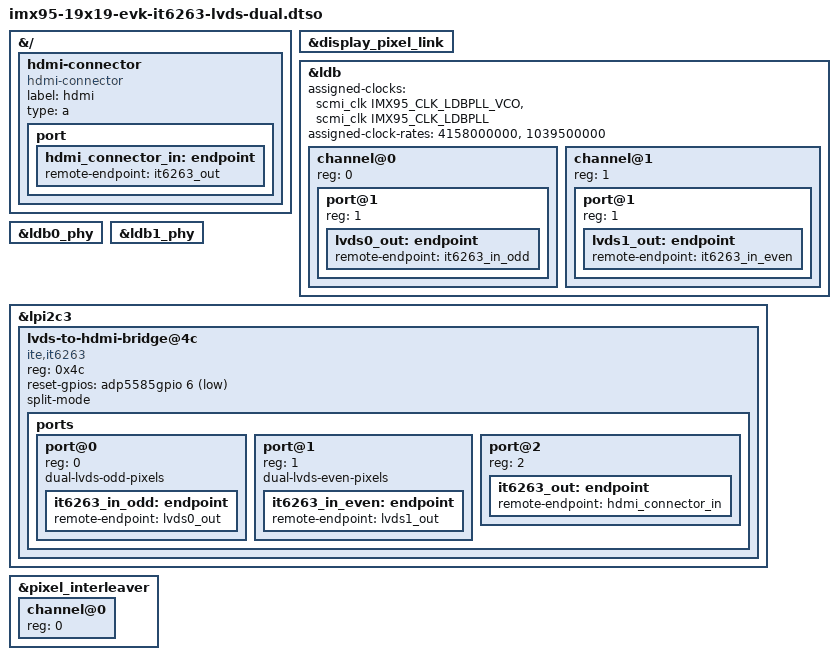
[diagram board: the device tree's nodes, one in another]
// SPDX-License-Identifier: (GPL-2.0+ OR MIT)
/*
 * Copyright 2023 NXP
 */

/dts-v1/;
/plugin/;

#include <dt-bindings/clock/fsl,imx95-clock.h>
#include <dt-bindings/gpio/gpio.h>

&{/} {
	hdmi-connector {
		compatible = "hdmi-connector";
		label = "hdmi";
		type = "a";

		port {
			hdmi_connector_in: endpoint {
				remote-endpoint = <&it6263_out>;
			};
		};
	};
};

&display_pixel_link {
	status = "okay";
};

&ldb {
	#address-cells = <1>;
	#size-cells = <0>;
	assigned-clocks = <&scmi_clk IMX95_CLK_LDBPLL_VCO>,
			  <&scmi_clk IMX95_CLK_LDBPLL>;
	assigned-clock-rates = <4158000000>, <1039500000>;
	status = "okay";

	channel@0 {
		#address-cells = <1>;
		#size-cells = <0>;
		reg = <0>;
		status = "okay";

		port@1 {
			reg = <1>;

			lvds0_out: endpoint {
				remote-endpoint = <&it6263_in_odd>;
			};
		};
	};

	channel@1 {
		#address-cells = <1>;
		#size-cells = <0>;
		reg = <1>;
		status = "okay";

		port@1 {
			reg = <1>;

			lvds1_out: endpoint {
				remote-endpoint = <&it6263_in_even>;
			};
		};
	};
};

&ldb0_phy {
	status = "okay";
};

&ldb1_phy {
	status = "okay";
};

&lpi2c3 {
	#address-cells = <1>;
	#size-cells = <0>;

	lvds-to-hdmi-bridge@4c {
		compatible = "ite,it6263";
		reg = <0x4c>;
		reset-gpios = <&adp5585gpio 6 GPIO_ACTIVE_LOW>;
		split-mode;

		ports {
			#address-cells = <1>;
			#size-cells = <0>;

			port@0 {
				reg = <0>;
				dual-lvds-odd-pixels;
				it6263_in_odd: endpoint {
					remote-endpoint = <&lvds0_out>;
				};
			};

			port@1 {
				reg = <1>;
				dual-lvds-even-pixels;
				it6263_in_even: endpoint {
					remote-endpoint = <&lvds1_out>;
				};
			};

			port@2 {
				reg = <2>;

				it6263_out: endpoint {
					remote-endpoint = <&hdmi_connector_in>;
				};
			};
		};
	};
};

&pixel_interleaver {
	#address-cells = <1>;
	#size-cells = <0>;
	status = "okay";

	channel@0 {
		reg = <0>;
		status = "okay";
	};
};
